AUTOSAR XML (schema 3.1.2)
package /Components/SWC_StopStrtEng
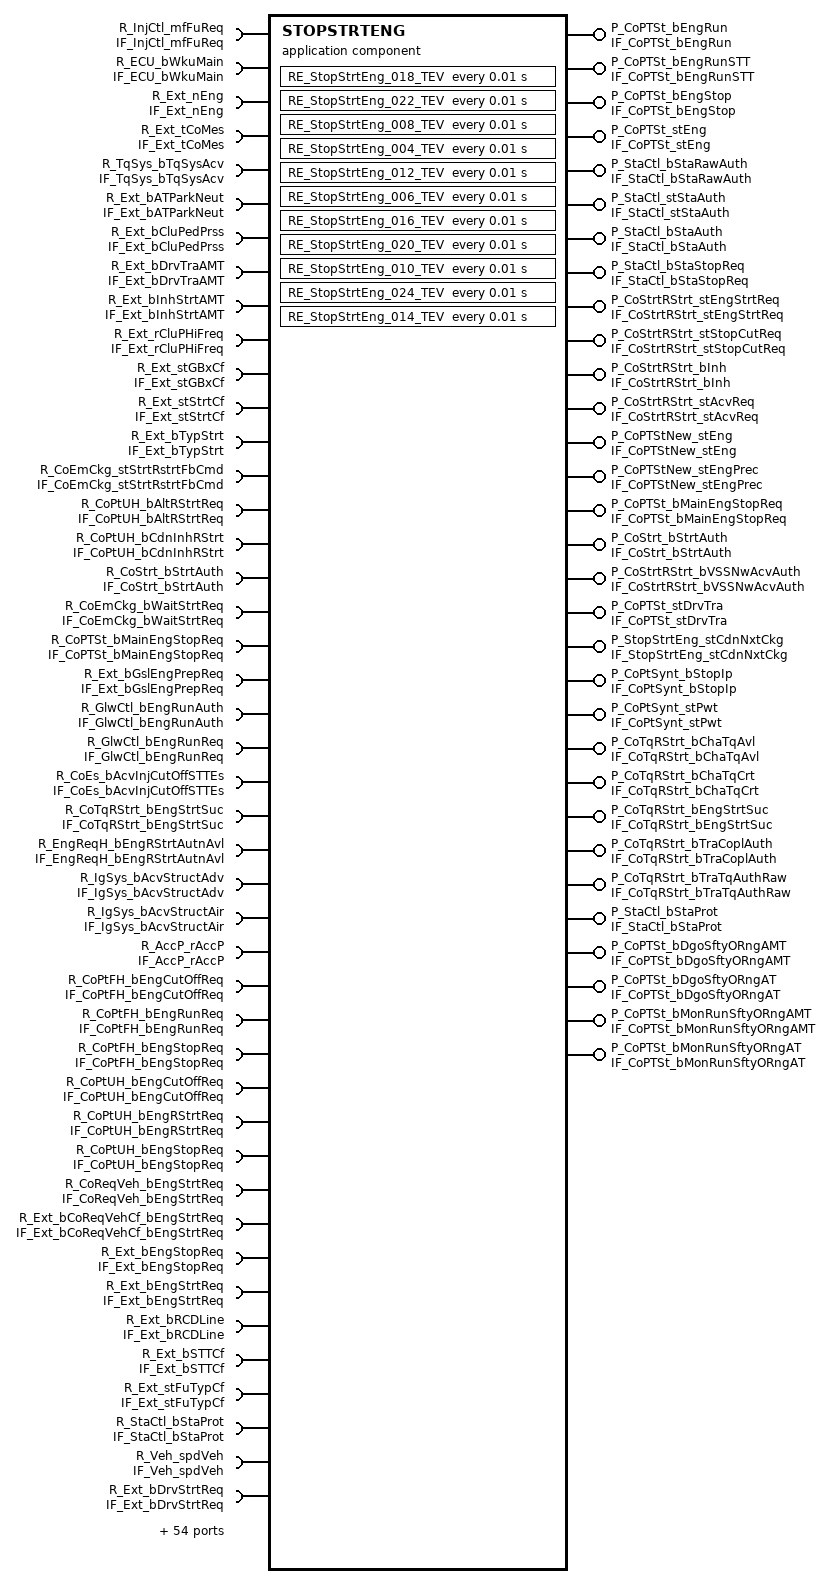
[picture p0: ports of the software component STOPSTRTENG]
  application software component type STOPSTRTENG
    91 x require port:
      R_InjCtl_mfFuReq: unqueued-receiver-com-spec{data-element=InjCtl_mfFuReq, init-value=InjCtl_mfFuReq_in, resync-time=0}, required-interface=IF_InjCtl_mfFuReq
      R_ECU_bWkuMain: unqueued-receiver-com-spec{data-element=ECU_bWkuMain, init-value=ConstantValue, resync-time=0}, required-interface=IF_ECU_bWkuMain
      R_Ext_nEng: unqueued-receiver-com-spec{data-element=Ext_nEng, init-value=ConstantValue1, resync-time=0}, required-interface=IF_Ext_nEng
      R_Ext_tCoMes: unqueued-receiver-com-spec{data-element=Ext_tCoMes, init-value=ConstantValue3, resync-time=0}, required-interface=IF_Ext_tCoMes
      R_TqSys_bTqSysAcv: unqueued-receiver-com-spec{data-element=TqSys_bTqSysAcv, init-value=TqSys_bTqSysAcv_in, resync-time=0}, required-interface=IF_TqSys_bTqSysAcv
      R_Ext_bATParkNeut: unqueued-receiver-com-spec{data-element=Ext_bATParkNeut, init-value=Ext_bATParkNeut_in, resync-time=0}, required-interface=IF_Ext_bATParkNeut
      R_Ext_bCluPedPrss: unqueued-receiver-com-spec{data-element=Ext_bCluPedPrss, init-value=ConstantValue5, resync-time=0}, required-interface=IF_Ext_bCluPedPrss
      R_Ext_bDrvTraAMT: unqueued-receiver-com-spec{data-element=Ext_bDrvTraAMT, init-value=Ext_bDrvTraAMT_in, resync-time=0}, required-interface=IF_Ext_bDrvTraAMT
      R_Ext_bInhStrtAMT: unqueued-receiver-com-spec{data-element=Ext_bInhStrtAMT, init-value=Ext_bInhStrtAMT_in, resync-time=0}, required-interface=IF_Ext_bInhStrtAMT
      R_Ext_rCluPHiFreq: unqueued-receiver-com-spec{data-element=Ext_rCluPHiFreq, init-value=ConstantValue7, resync-time=0}, required-interface=IF_Ext_rCluPHiFreq
      R_Ext_stGBxCf: unqueued-receiver-com-spec{data-element=Ext_stGBxCf, init-value=ConstantValue9, resync-time=0}, required-interface=IF_Ext_stGBxCf
      R_Ext_stStrtCf: unqueued-receiver-com-spec{data-element=Ext_stStrtCf, init-value=Ext_stStrtCf_in, resync-time=0}, required-interface=IF_Ext_stStrtCf
      R_Ext_bTypStrt: unqueued-receiver-com-spec{data-element=Ext_bTypStrt, init-value=Ext_bTypStrt_in, resync-time=0}, required-interface=IF_Ext_bTypStrt
      R_CoEmCkg_stStrtRstrtFbCmd: unqueued-receiver-com-spec{data-element=CoEmCkg_stStrtRstrtFbCmd, init-value=ConstantValue11, resync-time=0}, required-interface=IF_CoEmCkg_stStrtRstrtFbCmd
      R_CoPtUH_bAltRStrtReq: unqueued-receiver-com-spec{data-element=CoPtUH_bAltRStrtReq, init-value=ConstantValue13, resync-time=0}, required-interface=IF_CoPtUH_bAltRStrtReq
      R_CoPtUH_bCdnInhRStrt: unqueued-receiver-com-spec{data-element=CoPtUH_bCdnInhRStrt, init-value=ConstantValue15, resync-time=0}, required-interface=IF_CoPtUH_bCdnInhRStrt
      R_CoStrt_bStrtAuth: unqueued-receiver-com-spec{data-element=CoStrt_bStrtAuth, init-value=ConstantValue17, resync-time=0}, required-interface=IF_CoStrt_bStrtAuth
      R_CoEmCkg_bWaitStrtReq: unqueued-receiver-com-spec{data-element=CoEmCkg_bWaitStrtReq, init-value=ConstantValue19, resync-time=0}, required-interface=IF_CoEmCkg_bWaitStrtReq
      R_CoPTSt_bMainEngStopReq: unqueued-receiver-com-spec{data-element=CoPTSt_bMainEngStopReq, init-value=ConstantValue21, resync-time=0}, required-interface=IF_CoPTSt_bMainEngStopReq
      R_Ext_bGslEngPrepReq: unqueued-receiver-com-spec{data-element=Ext_bGslEngPrepReq, init-value=Ext_bGslEngPrepReq_in, resync-time=0}, required-interface=IF_Ext_bGslEngPrepReq
      R_GlwCtl_bEngRunAuth: unqueued-receiver-com-spec{data-element=GlwCtl_bEngRunAuth, init-value=GlwCtl_bEngRunAuth_in, resync-time=0}, required-interface=IF_GlwCtl_bEngRunAuth
      R_GlwCtl_bEngRunReq: unqueued-receiver-com-spec{data-element=GlwCtl_bEngRunReq, init-value=GlwCtl_bEngRunReq_in, resync-time=0}, required-interface=IF_GlwCtl_bEngRunReq
      R_CoEs_bAcvInjCutOffSTTEs: unqueued-receiver-com-spec{data-element=CoEs_bAcvInjCutOffSTTEs, init-value=CoEs_bAcvInjCutOffSTTEs_in, resync-time=0}, required-interface=IF_CoEs_bAcvInjCutOffSTTEs
      R_CoTqRStrt_bEngStrtSuc: unqueued-receiver-com-spec{data-element=CoTqRStrt_bEngStrtSuc, init-value=ConstantValue23, resync-time=0}, required-interface=IF_CoTqRStrt_bEngStrtSuc
      R_EngReqH_bEngRStrtAutnAvl: unqueued-receiver-com-spec{data-element=EngReqH_bEngRStrtAutnAvl, init-value=ConstantValue25, resync-time=0}, required-interface=IF_EngReqH_bEngRStrtAutnAvl
      R_IgSys_bAcvStructAdv: unqueued-receiver-com-spec{data-element=IgSys_bAcvStructAdv, init-value=ConstantValue27, resync-time=0}, required-interface=IF_IgSys_bAcvStructAdv
      R_IgSys_bAcvStructAir: unqueued-receiver-com-spec{data-element=IgSys_bAcvStructAir, init-value=ConstantValue29, resync-time=0}, required-interface=IF_IgSys_bAcvStructAir
      R_AccP_rAccP: unqueued-receiver-com-spec{data-element=AccP_rAccP, init-value=ConstantValue31, resync-time=0}, required-interface=IF_AccP_rAccP
      R_CoPtFH_bEngCutOffReq: unqueued-receiver-com-spec{data-element=CoPtFH_bEngCutOffReq, init-value=CoPtFH_bEngCutOffReq_in, resync-time=0}, required-interface=IF_CoPtFH_bEngCutOffReq
      R_CoPtFH_bEngRunReq: unqueued-receiver-com-spec{data-element=CoPtFH_bEngRunReq, init-value=CoPtFH_bEngRunReq_in, resync-time=0}, required-interface=IF_CoPtFH_bEngRunReq
      R_CoPtFH_bEngStopReq: unqueued-receiver-com-spec{data-element=CoPtFH_bEngStopReq, init-value=CoPtFH_bEngStopReq_in, resync-time=0}, required-interface=IF_CoPtFH_bEngStopReq
      R_CoPtUH_bEngCutOffReq: unqueued-receiver-com-spec{data-element=CoPtUH_bEngCutOffReq, init-value=ConstantValue33, resync-time=0}, required-interface=IF_CoPtUH_bEngCutOffReq
      R_CoPtUH_bEngRStrtReq: unqueued-receiver-com-spec{data-element=CoPtUH_bEngRStrtReq, init-value=ConstantValue35, resync-time=0}, required-interface=IF_CoPtUH_bEngRStrtReq
      R_CoPtUH_bEngStopReq: unqueued-receiver-com-spec{data-element=CoPtUH_bEngStopReq, init-value=ConstantValue37, resync-time=0}, required-interface=IF_CoPtUH_bEngStopReq
      R_CoReqVeh_bEngStrtReq: unqueued-receiver-com-spec{data-element=CoReqVeh_bEngStrtReq, init-value=CoReqVeh_bEngStrtReq_in, resync-time=0}, required-interface=IF_CoReqVeh_bEngStrtReq
      R_Ext_bCoReqVehCf_bEngStrtReq: unqueued-receiver-com-spec{data-element=Ext_bCoReqVehCf_bEngStrtReq, init-value=Ext_bCoReqVehCf_bEngStrtReq_in, resync-time=0}, required-interface=IF_Ext_bCoReqVehCf_bEngStrtReq
      R_Ext_bEngStopReq: unqueued-receiver-com-spec{data-element=Ext_bEngStopReq, init-value=Ext_bEngStopReq_in, resync-time=0}, required-interface=IF_Ext_bEngStopReq
      R_Ext_bEngStrtReq: unqueued-receiver-com-spec{data-element=Ext_bEngStrtReq, init-value=Ext_bEngStrtReq_in, resync-time=0}, required-interface=IF_Ext_bEngStrtReq
      R_Ext_bRCDLine: unqueued-receiver-com-spec{data-element=Ext_bRCDLine, init-value=ConstantValue39, resync-time=0}, required-interface=IF_Ext_bRCDLine
      R_Ext_bSTTCf: unqueued-receiver-com-spec{data-element=Ext_bSTTCf, init-value=ConstantValue41, resync-time=0}, required-interface=IF_Ext_bSTTCf
      R_Ext_stFuTypCf: unqueued-receiver-com-spec{data-element=Ext_stFuTypCf, init-value=ConstantValue43, resync-time=0}, required-interface=IF_Ext_stFuTypCf
      R_StaCtl_bStaProt: unqueued-receiver-com-spec{data-element=StaCtl_bStaProt, init-value=StaCtl_bStaProt_in, resync-time=0}, required-interface=IF_StaCtl_bStaProt
      R_Veh_spdVeh: unqueued-receiver-com-spec{data-element=Veh_spdVeh, init-value=ConstantValue45, resync-time=0}, required-interface=IF_Veh_spdVeh
      R_Ext_bDrvStrtReq: unqueued-receiver-com-spec{data-element=Ext_bDrvStrtReq, init-value=Ext_bDrvStrtReq_in, resync-time=0}, required-interface=IF_Ext_bDrvStrtReq
      R_StaCtl_bStaAuth: unqueued-receiver-com-spec{data-element=StaCtl_bStaAuth, init-value=StaCtl_bStaAuth_in, resync-time=0}, required-interface=IF_StaCtl_bStaAuth
      R_Ext_bBrkPedPrss: unqueued-receiver-com-spec{data-element=Ext_bBrkPedPrss, init-value=ConstantValue47, resync-time=0}, required-interface=IF_Ext_bBrkPedPrss
      R_Ext_posnGBxLev: unqueued-receiver-com-spec{data-element=Ext_posnGBxLev, init-value=ConstantValue49, resync-time=0}, required-interface=IF_Ext_posnGBxLev
      R_CoPtASE_bAltRStrtTypASEReq: unqueued-receiver-com-spec{data-element=CoPtASE_bAltRStrtTypASEReq, init-value=ConstantValue51, resync-time=0}, required-interface=IF_CoPtASE_bAltRStrtTypASEReq
      R_CoPtASE_bAltStrtTypASEReq: unqueued-receiver-com-spec{data-element=CoPtASE_bAltStrtTypASEReq, init-value=CoPtASE_bAltStrtTypASEReq_in, resync-time=0}, required-interface=IF_CoPtASE_bAltStrtTypASEReq
      R_CoPtASE_bCdnInhRStrt: unqueued-receiver-com-spec{data-element=CoPtASE_bCdnInhRStrt, init-value=ConstantValue53, resync-time=0}, required-interface=IF_CoPtASE_bCdnInhRStrt
      R_CoPtASE_bEngCutOffReq: unqueued-receiver-com-spec{data-element=CoPtASE_bEngCutOffReq, init-value=ConstantValue55, resync-time=0}, required-interface=IF_CoPtASE_bEngCutOffReq
      R_CoPtASE_bEngRStrtTypASEReq: unqueued-receiver-com-spec{data-element=CoPtASE_bEngRStrtTypASEReq, init-value=ConstantValue57, resync-time=0}, required-interface=IF_CoPtASE_bEngRStrtTypASEReq
      R_CoPtASE_bEngStallReq: unqueued-receiver-com-spec{data-element=CoPtASE_bEngStallReq, init-value=ConstantValue59, resync-time=0}, required-interface=IF_CoPtASE_bEngStallReq
      R_CoPtASE_bEngStrtTypASEReq: unqueued-receiver-com-spec{data-element=CoPtASE_bEngStrtTypASEReq, init-value=CoPtASE_bEngStrtTypASEReq_in, resync-time=0}, required-interface=IF_CoPtASE_bEngStrtTypASEReq
      R_CoPtASE_bVSSNwAcvAuth: unqueued-receiver-com-spec{data-element=CoPtASE_bVSSNwAcvAuth, init-value=ConstantValue61, resync-time=0}, required-interface=IF_CoPtASE_bVSSNwAcvAuth
      R_CoPTStNew_stEng: unqueued-receiver-com-spec{data-element=CoPTStNew_stEng, init-value=ConstantValue63, resync-time=0}, required-interface=IF_CoPTStNew_stEng
      R_CoPtUH_bVSSNwAcvAuth: unqueued-receiver-com-spec{data-element=CoPtUH_bVSSNwAcvAuth, init-value=ConstantValue65, resync-time=0}, required-interface=IF_CoPtUH_bVSSNwAcvAuth
      R_CoPtUH_bEngStallReq: unqueued-receiver-com-spec{data-element=CoPtUH_bEngStallReq, init-value=ConstantValue67, resync-time=0}, required-interface=IF_CoPtUH_bEngStallReq
      R_CoSync_bDetNNull: unqueued-receiver-com-spec{data-element=CoSync_bDetNNull, init-value=ConstantValue69, resync-time=0}, required-interface=IF_CoSync_bDetNNull
      R_Ext_bASECf: unqueued-receiver-com-spec{data-element=Ext_bASECf, init-value=Ext_bASECf_in, resync-time=0}, required-interface=IF_Ext_bASECf
      R_TqAdp_stCdnNxtCkg: unqueued-receiver-com-spec{data-element=TqAdp_stCdnNxtCkg, init-value=TqAdp_stCdnNxtCkg_in, resync-time=0}, required-interface=IF_TqAdp_stCdnNxtCkg
      R_CoOptmEl_stElEProv: unqueued-receiver-com-spec{data-element=CoOptmEl_stElEProv, init-value=ConstantValue71, resync-time=0}, required-interface=IF_CoOptmEl_stElEProv
      R_CoPtASE_stPwt: unqueued-receiver-com-spec{data-element=CoPtASE_stPwt, init-value=ConstantValue73, resync-time=0}, required-interface=IF_CoPtASE_stPwt
      R_CoPtUH_stPwt: unqueued-receiver-com-spec{data-element=CoPtUH_stPwt, init-value=ConstantValue75, resync-time=0}, required-interface=IF_CoPtUH_stPwt
      R_CoPTSt_stDrvTra: unqueued-receiver-com-spec{data-element=CoPTSt_stDrvTra, init-value=CoPTSt_stDrvTra_in, resync-time=0}, required-interface=IF_CoPTSt_stDrvTra
      R_TqSys_nTarIdl: unqueued-receiver-com-spec{data-element=TqSys_nTarIdl, init-value=ConstantValue77, resync-time=0}, required-interface=IF_TqSys_nTarIdl
      R_Ext_tOilMes: unqueued-receiver-com-spec{data-element=Ext_tOilMes, init-value=ConstantValue79, resync-time=0}, required-interface=IF_Ext_tOilMes
      R_PredEs_nFast: unqueued-receiver-com-spec{data-element=PredEs_nFast, init-value=ConstantValue81, resync-time=0}, required-interface=IF_PredEs_nFast
      R_CoPt_bSIP: unqueued-receiver-com-spec{data-element=CoPt_bSIP, init-value=ConstantValue83, resync-time=0}, required-interface=IF_CoPt_bSIP
      R_Ext_pAirExtMes: unqueued-receiver-com-spec{data-element=Ext_pAirExtMes, init-value=ConstantValue85, resync-time=0}, required-interface=IF_Ext_pAirExtMes
      R_Afts_bSpcFactOffDeacInh: unqueued-receiver-com-spec{data-element=Afts_bSpcFactOffDeacInh, init-value=Afts_bSpcFactOffDeacInh_in, resync-time=0}, required-interface=IF_Afts_bSpcFactOffDeacInh
      R_Afts_bSpcFactOnDeacInh: unqueued-receiver-com-spec{data-element=Afts_bSpcFactOnDeacInh, init-value=Afts_bSpcFactOnDeacInh_in, resync-time=0}, required-interface=IF_Afts_bSpcFactOnDeacInh
      R_CoTqRStrt_bTraTqAuthRaw: unqueued-receiver-com-spec{data-element=CoTqRStrt_bTraTqAuthRaw, init-value=ConstantValue87, resync-time=0}, required-interface=IF_CoTqRStrt_bTraTqAuthRaw
      R_PARM_bEngRstrtAutnAvl: unqueued-receiver-com-spec{data-element=PARM_bEngRstrtAutnAvl, init-value=ConstantValue89, resync-time=0}, required-interface=IF_PARM_bEngRstrtAutnAvl
      R_CoEmSTT_tiVSSTmrStrtAuth: unqueued-receiver-com-spec{data-element=CoEmSTT_tiVSSTmrStrtAuth, init-value=ConstantValue91, resync-time=0}, required-interface=IF_CoEmSTT_tiVSSTmrStrtAuth
      R_EngReqH_bDetPresAirUnfav: unqueued-receiver-com-spec{data-element=EngReqH_bDetPresAirUnfav, init-value=EngReqH_bDetPresAirUnfav_in, resync-time=0}, required-interface=IF_EngReqH_bDetPresAirUnfav
      R_CoPTSt_bEngRunSTT: unqueued-receiver-com-spec{data-element=CoPTSt_bEngRunSTT, init-value=CoPTSt_bEngRunSTT_in, resync-time=0}, required-interface=IF_CoPTSt_bEngRunSTT
      R_Ext_bDgoSenPN: unqueued-receiver-com-spec{data-element=Ext_bDgoSenPN, init-value=Ext_bDgoSenPN_in, resync-time=0}, required-interface=IF_Ext_bDgoSenPN
      R_Ext_bAcvInjCutOff: unqueued-receiver-com-spec{data-element=Ext_bAcvInjCutOff, init-value=Ext_bAcvInjCutOff_in, resync-time=0}, required-interface=IF_Ext_bAcvInjCutOff
      R_Sfty_bInhDrvTraSfty: unqueued-receiver-com-spec{data-element=Sfty_bInhDrvTraSfty, init-value=Sfty_bInhDrvTraSfty_in, resync-time=0}, required-interface=IF_Sfty_bInhDrvTraSfty
      R_FRM_bAcvDrvTraInvld: required-interface=FunctionInhibition
      R_FRM_bInhSta: required-interface=FunctionInhibition
      R_FRM_bAcvCoPTStByp_nEng: required-interface=FunctionInhibition
      R_FRM_bAcvCoPTStByp_spdVeh: required-interface=FunctionInhibition
      R_FRM_bAcvCoPTStEngStop: required-interface=FunctionInhibition
      R_FRM_bAcvEngCutOffRCDLo: required-interface=FunctionInhibition
      R_FRM_bInhEngCutOff: required-interface=FunctionInhibition
      R_FRM_bInhSTT: required-interface=FunctionInhibition
      R_FRM_bAcvEngCutOff: required-interface=FunctionInhibition
      R_FRM_bStrtPrf: required-interface=FunctionInhibition
      R_FRM_bAcvPrmCoTqRStrt: required-interface=FunctionInhibition
    27 x provide port:
      P_CoPTSt_bEngRun: unqueued-sender-com-spec{data-element=CoPTSt_bEngRun, can-invalidate=false, init-value=CoPTSt_bEngRun_out}, provided-interface=IF_CoPTSt_bEngRun
      P_CoPTSt_bEngRunSTT: unqueued-sender-com-spec{data-element=CoPTSt_bEngRunSTT, can-invalidate=false, init-value=CoPTSt_bEngRunSTT_out}, provided-interface=IF_CoPTSt_bEngRunSTT
      P_CoPTSt_bEngStop: unqueued-sender-com-spec{data-element=CoPTSt_bEngStop, can-invalidate=false, init-value=CoPTSt_bEngStop_out}, provided-interface=IF_CoPTSt_bEngStop
      P_CoPTSt_stEng: unqueued-sender-com-spec{data-element=CoPTSt_stEng, can-invalidate=false, init-value=ConstantValue93}, provided-interface=IF_CoPTSt_stEng
      P_StaCtl_bStaRawAuth: unqueued-sender-com-spec{data-element=StaCtl_bStaRawAuth, can-invalidate=false, init-value=StaCtl_bStaRawAuth_out}, provided-interface=IF_StaCtl_bStaRawAuth
      P_StaCtl_stStaAuth: unqueued-sender-com-spec{data-element=StaCtl_stStaAuth, can-invalidate=false, init-value=StaCtl_stStaAuth_out}, provided-interface=IF_StaCtl_stStaAuth
      P_StaCtl_bStaAuth: unqueued-sender-com-spec{data-element=StaCtl_bStaAuth, can-invalidate=false, init-value=StaCtl_bStaAuth_out}, provided-interface=IF_StaCtl_bStaAuth
      P_StaCtl_bStaStopReq: unqueued-sender-com-spec{data-element=StaCtl_bStaStopReq, can-invalidate=false, init-value=StaCtl_bStaStopReq_out}, provided-interface=IF_StaCtl_bStaStopReq
      P_CoStrtRStrt_stEngStrtReq: unqueued-sender-com-spec{data-element=CoStrtRStrt_stEngStrtReq, can-invalidate=false, init-value=ConstantValue95}, provided-interface=IF_CoStrtRStrt_stEngStrtReq
      P_CoStrtRStrt_stStopCutReq: unqueued-sender-com-spec{data-element=CoStrtRStrt_stStopCutReq, can-invalidate=false, init-value=CoStrtRStrt_stStopCutReq_out}, provided-interface=IF_CoStrtRStrt_stStopCutReq
      P_CoStrtRStrt_bInh: unqueued-sender-com-spec{data-element=CoStrtRStrt_bInh, can-invalidate=false, init-value=ConstantValue97}, provided-interface=IF_CoStrtRStrt_bInh
      P_CoStrtRStrt_stAcvReq: unqueued-sender-com-spec{data-element=CoStrtRStrt_stAcvReq, can-invalidate=false, init-value=ConstantValue99}, provided-interface=IF_CoStrtRStrt_stAcvReq
      P_CoPTStNew_stEng: unqueued-sender-com-spec{data-element=CoPTStNew_stEng, can-invalidate=false, init-value=ConstantValue101}, provided-interface=IF_CoPTStNew_stEng
      P_CoPTStNew_stEngPrec: unqueued-sender-com-spec{data-element=CoPTStNew_stEngPrec, can-invalidate=false, init-value=CoPTStNew_stEngPrec_out}, provided-interface=IF_CoPTStNew_stEngPrec
      P_CoPTSt_bMainEngStopReq: unqueued-sender-com-spec{data-element=CoPTSt_bMainEngStopReq, can-invalidate=false, init-value=ConstantValue103}, provided-interface=IF_CoPTSt_bMainEngStopReq
      P_CoStrt_bStrtAuth: unqueued-sender-com-spec{data-element=CoStrt_bStrtAuth, can-invalidate=false, init-value=ConstantValue105}, provided-interface=IF_CoStrt_bStrtAuth
      P_CoStrtRStrt_bVSSNwAcvAuth: unqueued-sender-com-spec{data-element=CoStrtRStrt_bVSSNwAcvAuth, can-invalidate=false, init-value=CoStrtRStrt_bVSSNwAcvAuth_out}, provided-interface=IF_CoStrtRStrt_bVSSNwAcvAuth
      P_CoPTSt_stDrvTra: unqueued-sender-com-spec{data-element=CoPTSt_stDrvTra, can-invalidate=false, init-value=CoPTSt_stDrvTra_out}, provided-interface=IF_CoPTSt_stDrvTra
      P_StopStrtEng_stCdnNxtCkg: unqueued-sender-com-spec{data-element=StopStrtEng_stCdnNxtCkg, can-invalidate=false, init-value=ConstantValue107}, provided-interface=IF_StopStrtEng_stCdnNxtCkg
      P_CoPtSynt_bStopIp: unqueued-sender-com-spec{data-element=CoPtSynt_bStopIp, can-invalidate=false, init-value=CoPtSynt_bStopIp_out}, provided-interface=IF_CoPtSynt_bStopIp
      P_CoPtSynt_stPwt: unqueued-sender-com-spec{data-element=CoPtSynt_stPwt, can-invalidate=false, init-value=ConstantValue109}, provided-interface=IF_CoPtSynt_stPwt
      P_CoTqRStrt_bChaTqAvl: unqueued-sender-com-spec{data-element=CoTqRStrt_bChaTqAvl, can-invalidate=false, init-value=CoTqRStrt_bChaTqAvl_out}, provided-interface=IF_CoTqRStrt_bChaTqAvl
      P_CoTqRStrt_bChaTqCrt: unqueued-sender-com-spec{data-element=CoTqRStrt_bChaTqCrt, can-invalidate=false, init-value=CoTqRStrt_bChaTqCrt_out}, provided-interface=IF_CoTqRStrt_bChaTqCrt
      P_CoTqRStrt_bEngStrtSuc: unqueued-sender-com-spec{data-element=CoTqRStrt_bEngStrtSuc, can-invalidate=false, init-value=ConstantValue111}, provided-interface=IF_CoTqRStrt_bEngStrtSuc
      P_CoTqRStrt_bTraCoplAuth: unqueued-sender-com-spec{data-element=CoTqRStrt_bTraCoplAuth, can-invalidate=false, init-value=CoTqRStrt_bTraCoplAuth_out}, provided-interface=IF_CoTqRStrt_bTraCoplAuth
      P_CoTqRStrt_bTraTqAuthRaw: unqueued-sender-com-spec{data-element=CoTqRStrt_bTraTqAuthRaw, can-invalidate=false, init-value=ConstantValue113}, provided-interface=IF_CoTqRStrt_bTraTqAuthRaw
      P_StaCtl_bStaProt: unqueued-sender-com-spec{data-element=StaCtl_bStaProt, can-invalidate=false, init-value=StaCtl_bStaProt_out}, provided-interface=IF_StaCtl_bStaProt
    7 x require port:
      R_CoSTT_ORngCutOffReq: required-interface=DiagnosticMonitor
      R_CoSTT_ORngStopReq: required-interface=DiagnosticMonitor
      R_CoPTSt_ORngMplReq: required-interface=DiagnosticMonitor
      R_CoPTSt_SftyORngAMT: required-interface=DiagnosticMonitor
      R_CoPTSt_SftyORngAT: required-interface=DiagnosticMonitor
      R_UCE_stWkuMainRelSt: required-interface=IF_UCE_stWkuMainRelSt
      R_EcuM_CurrentMode: required-interface=EcuM_CurrentMode
    4 x provide port:
      P_CoPTSt_bDgoSftyORngAMT: unqueued-sender-com-spec{data-element=CoPTSt_bDgoSftyORngAMT, can-invalidate=false, init-value=CoPTSt_bDgoSftyORngAMT_Cst}, provided-interface=IF_CoPTSt_bDgoSftyORngAMT
      P_CoPTSt_bDgoSftyORngAT: unqueued-sender-com-spec{data-element=CoPTSt_bDgoSftyORngAT, can-invalidate=false, init-value=CoPTSt_bDgoSftyORngAT_Cst}, provided-interface=IF_CoPTSt_bDgoSftyORngAT
      P_CoPTSt_bMonRunSftyORngAMT: unqueued-sender-com-spec{data-element=CoPTSt_bMonRunSftyORngAMT, can-invalidate=false, init-value=CoPTSt_bMonRunSftyORngAMT_Cst}, provided-interface=IF_CoPTSt_bMonRunSftyORngAMT
      P_CoPTSt_bMonRunSftyORngAT: unqueued-sender-com-spec{data-element=CoPTSt_bMonRunSftyORngAT, can-invalidate=false, init-value=CoPTSt_bMonRunSftyORngAT_Cst}, provided-interface=IF_CoPTSt_bMonRunSftyORngAT
  125 x constant specification:
    Afts_bSpcFactOffDeacInh_in
      value:
        boolean literal Afts_bSpcFactOffDeacInh_in: type=DT_Afts_bSpcFactOffDeacInh, value=true
    Afts_bSpcFactOnDeacInh_in
      value:
        boolean literal Afts_bSpcFactOnDeacInh_in: type=DT_Afts_bSpcFactOnDeacInh, value=false
    CoEs_bAcvInjCutOffSTTEs_in
      value:
        boolean literal CoEs_bAcvInjCutOffSTTEs_in: type=DT_CoEs_bAcvInjCutOffSTTEs, value=false
    ConstantValue
      value:
        boolean literal ConstantValue: type=DT_ECU_bWkuMain, value=false
    ConstantValue1
      value:
        integer literal ConstantValue1: type=DT_Ext_nEng, value=0
    ConstantValue101
      value:
        integer literal ConstantValue101: type=DT_CoPTStNew_stEng, value=1
    ConstantValue103
      value:
        boolean literal ConstantValue103: type=DT_CoPTSt_bMainEngStopReq, value=false
    ConstantValue105
      value:
        boolean literal ConstantValue105: type=DT_CoStrt_bStrtAuth, value=false
    ConstantValue107
      value:
        integer literal ConstantValue107: type=DT_StopStrtEng_stCdnNxtCkg, value=0
    ConstantValue109
      value:
        integer literal ConstantValue109: type=DT_CoPtSynt_stPwt, value=1
    ConstantValue11
      value:
        integer literal ConstantValue11: type=DT_CoEmCkg_stStrtRstrtFbCmd, value=0
    ConstantValue111
      value:
        boolean literal ConstantValue111: type=DT_CoTqRStrt_bEngStrtSuc, value=false
    ConstantValue113
      value:
        boolean literal ConstantValue113: type=DT_CoTqRStrt_bTraTqAuthRaw, value=false
    ConstantValue13
      value:
        boolean literal ConstantValue13: type=DT_CoPtUH_bAltRStrtReq, value=false
    ConstantValue15
      value:
        boolean literal ConstantValue15: type=DT_CoPtUH_bCdnInhRStrt, value=false
    ConstantValue17
      value:
        boolean literal ConstantValue17: type=DT_CoStrt_bStrtAuth, value=false
    ConstantValue19
      value:
        boolean literal ConstantValue19: type=DT_CoEmCkg_bWaitStrtReq, value=false
    ConstantValue21
      value:
        boolean literal ConstantValue21: type=DT_CoPTSt_bMainEngStopReq, value=false
    ConstantValue23
      value:
        boolean literal ConstantValue23: type=DT_CoTqRStrt_bEngStrtSuc, value=false
    ConstantValue25
      value:
        boolean literal ConstantValue25: type=DT_EngReqH_bEngRStrtAutnAvl, value=false
    ConstantValue27
      value:
        boolean literal ConstantValue27: type=DT_IgSys_bAcvStructAdv, value=false
    ConstantValue29
      value:
        boolean literal ConstantValue29: type=DT_IgSys_bAcvStructAir, value=false
    ConstantValue3
      value:
        integer literal ConstantValue3: type=DT_Ext_tCoMes, value=20
    ConstantValue31
      value:
        integer literal ConstantValue31: type=DT_AccP_rAccP, value=0
    ConstantValue33
      value:
        boolean literal ConstantValue33: type=DT_CoPtUH_bEngCutOffReq, value=false
    ConstantValue35
      value:
        boolean literal ConstantValue35: type=DT_CoPtUH_bEngRStrtReq, value=false
    ConstantValue37
      value:
        boolean literal ConstantValue37: type=DT_CoPtUH_bEngStopReq, value=false
    ConstantValue39
      value:
        boolean literal ConstantValue39: type=DT_Ext_bRCDLine, value=false
    ConstantValue41
      value:
        boolean literal ConstantValue41: type=DT_Ext_bSTTCf, value=false
    ConstantValue43
      value:
        integer literal ConstantValue43: type=DT_Ext_stFuTypCf, value=0
    ConstantValue45
      value:
        integer literal ConstantValue45: type=DT_Veh_spdVeh, value=0
    ConstantValue47
      value:
        boolean literal ConstantValue47: type=DT_Ext_bBrkPedPrss, value=false
    ConstantValue49
      value:
        integer literal ConstantValue49: type=DT_Ext_posnGBxLev, value=0
    ConstantValue5
      value:
        boolean literal ConstantValue5: type=DT_Ext_bCluPedPrss, value=false
    ConstantValue51
      value:
        boolean literal ConstantValue51: type=DT_CoPtASE_bAltRStrtTypASEReq, value=false
    ConstantValue53
      value:
        boolean literal ConstantValue53: type=DT_CoPtASE_bCdnInhRStrt, value=true
    ConstantValue55
      value:
        boolean literal ConstantValue55: type=DT_CoPtASE_bEngCutOffReq, value=false
    ConstantValue57
      value:
        boolean literal ConstantValue57: type=DT_CoPtASE_bEngRStrtTypASEReq, value=false
    ConstantValue59
      value:
        boolean literal ConstantValue59: type=DT_CoPtASE_bEngStallReq, value=false
    ConstantValue61
      value:
        boolean literal ConstantValue61: type=DT_CoPtASE_bVSSNwAcvAuth, value=false
    ConstantValue63
      value:
        integer literal ConstantValue63: type=DT_CoPTStNew_stEng, value=1
    ConstantValue65
      value:
        boolean literal ConstantValue65: type=DT_CoPtUH_bVSSNwAcvAuth, value=false
    ConstantValue67
      value:
        boolean literal ConstantValue67: type=DT_CoPtUH_bEngStallReq, value=false
    ConstantValue69
      value:
        boolean literal ConstantValue69: type=DT_CoSync_bDetNNull, value=false
    ConstantValue7
      value:
        integer literal ConstantValue7: type=DT_Ext_rCluPHiFreq, value=0
    ConstantValue71
      value:
        integer literal ConstantValue71: type=DT_CoOptmEl_stElEProv, value=1
    ConstantValue73
      value:
        integer literal ConstantValue73: type=DT_CoPtASE_stPwt, value=1
    ConstantValue75
      value:
        integer literal ConstantValue75: type=DT_CoPtUH_stPwt, value=1
    ConstantValue77
      value:
        integer literal ConstantValue77: type=DT_TqSys_nTarIdl, value=0
    ConstantValue79
      value:
        integer literal ConstantValue79: type=DT_Ext_tOilMes, value=0
    ConstantValue81
      value:
        integer literal ConstantValue81: type=DT_PredEs_nFast, value=0
    ConstantValue83
      value:
        boolean literal ConstantValue83: type=DT_CoPt_bSIP, value=false
    ConstantValue85
      value:
        integer literal ConstantValue85: type=DT_Ext_pAirExtMes, value=500
    ConstantValue87
      value:
        boolean literal ConstantValue87: type=DT_CoTqRStrt_bTraTqAuthRaw, value=false
    ConstantValue89
      value:
        boolean literal ConstantValue89: type=DT_PARM_bEngRstrtAutnAvl, value=false
    ConstantValue9
      value:
        integer literal ConstantValue9: type=DT_Ext_stGBxCf, value=0
    ConstantValue91
      value:
        integer literal ConstantValue91: type=DT_CoEmSTT_tiVSSTmrStrtAuth, value=0
    ConstantValue93
      value:
        integer literal ConstantValue93: type=DT_CoPTSt_stEng, value=1
    ConstantValue95
      value:
        integer literal ConstantValue95: type=DT_CoStrtRStrt_stEngStrtReq, value=0
    ConstantValue97
      value:
        boolean literal ConstantValue97: type=DT_CoStrtRStrt_bInh, value=true
    ConstantValue99
      value:
        integer literal ConstantValue99: type=DT_CoStrtRStrt_stAcvReq, value=0
    CoPtASE_bAltStrtTypASEReq_in
      value:
        boolean literal CoPtASE_bAltStrtTypASEReq_in: type=DT_CoPtASE_bAltStrtTypASEReq, value=false
    CoPtASE_bEngStrtTypASEReq_in
      value:
        boolean literal CoPtASE_bEngStrtTypASEReq_in: type=DT_CoPtASE_bEngStrtTypASEReq, value=false
    CoPtFH_bEngCutOffReq_in
      value:
        boolean literal CoPtFH_bEngCutOffReq_in: type=DT_CoPtFH_bEngCutOffReq, value=false
    CoPtFH_bEngRunReq_in
      value:
        boolean literal CoPtFH_bEngRunReq_in: type=DT_CoPtFH_bEngRunReq, value=false
    CoPtFH_bEngStopReq_in
      value:
        boolean literal CoPtFH_bEngStopReq_in: type=DT_CoPtFH_bEngStopReq, value=true
    CoPTSt_bDgoSftyORngAMT_Cst
      value:
        boolean literal CoPTSt_bDgoSftyORngAMT_Cst: type=DT_CoPTSt_bDgoSftyORngAMT, value=false
    CoPTSt_bDgoSftyORngAT_Cst
      value:
        boolean literal CoPTSt_bDgoSftyORngAT_Cst: type=DT_CoPTSt_bDgoSftyORngAT, value=false
    CoPTSt_bEngRun_out
      value:
        boolean literal CoPTSt_bEngRun_out: type=DT_CoPTSt_bEngRun, value=false
    CoPTSt_bEngRunSTT_in
      value:
        boolean literal CoPTSt_bEngRunSTT_in: type=DT_CoPTSt_bEngRunSTT, value=false
    CoPTSt_bEngRunSTT_out
      value:
        boolean literal CoPTSt_bEngRunSTT_out: type=DT_CoPTSt_bEngRunSTT, value=false
    CoPTSt_bEngStop_out
      value:
        boolean literal CoPTSt_bEngStop_out: type=DT_CoPTSt_bEngStop, value=true
    CoPTSt_bEngStopReq_Cst
      value:
        boolean literal CoPTSt_bEngStopReq_Cst: type=DT_CoPTSt_bEngStopReq, value=false
    CoPTSt_bEngStrtGlblReq_Cst
      value:
        boolean literal CoPTSt_bEngStrtGlblReq_Cst: type=DT_CoPTSt_bEngStrtGlblReq, value=true
    CoPTSt_bEngStrtReqVld_Cst
      value:
        boolean literal CoPTSt_bEngStrtReqVld_Cst: type=DT_CoPTSt_bEngStrtReqVld, value=false
    CoPTSt_bMonRunSftyORngAMT_Cst
      value:
        boolean literal CoPTSt_bMonRunSftyORngAMT_Cst: type=DT_CoPTSt_bMonRunSftyORngAMT, value=false
    CoPTSt_bMonRunSftyORngAT_Cst
      value:
        boolean literal CoPTSt_bMonRunSftyORngAT_Cst: type=DT_CoPTSt_bMonRunSftyORngAT, value=false
    CoPTSt_stDrvTra_in
      value:
        integer literal CoPTSt_stDrvTra_in: type=DT_CoPTSt_stDrvTra, value=1
    CoPTSt_stDrvTra_out
      value:
        integer literal CoPTSt_stDrvTra_out: type=DT_CoPTSt_stDrvTra, value=1
    CoPTStNew_stEngPrec_out
      value:
        integer literal CoPTStNew_stEngPrec_out: type=DT_CoPTStNew_stEngPrec, value=12
    CoPtSynt_bStopIp_out
      value:
        boolean literal CoPtSynt_bStopIp_out: type=DT_CoPtSynt_bStopIp, value=false
    CoReqVeh_bEngStrtReq_in
      value:
        boolean literal CoReqVeh_bEngStrtReq_in: type=DT_CoReqVeh_bEngStrtReq, value=false
    CoStrt_bStrtReq_Cst
      value:
        boolean literal CoStrt_bStrtReq_Cst: type=DT_CoStrt_bStrtReq, value=false
    CoStrtRStrt_bVSSNwAcvAuth_out
      value:
        boolean literal CoStrtRStrt_bVSSNwAcvAuth_out: type=DT_CoStrtRStrt_bVSSNwAcvAuth, value=false
    CoStrtRStrt_stStopCutReq_out
      value:
        integer literal CoStrtRStrt_stStopCutReq_out: type=DT_CoStrtRStrt_stStopCutReq, value=0
    CoSTT_bEngCutOffReq_Cst
      value:
        boolean literal CoSTT_bEngCutOffReq_Cst: type=DT_CoSTT_bEngCutOffReq, value=false
    CoSTT_bEngRStrtReq_Cst
      value:
        boolean literal CoSTT_bEngRStrtReq_Cst: type=DT_CoSTT_bEngRStrtReq, value=false
    CoSTT_bEngStopReq_Cst
      value:
        boolean literal CoSTT_bEngStopReq_Cst: type=DT_CoSTT_bEngStopReq, value=false
    CoTqRStrt_bChaTqAvl_out
      value:
        boolean literal CoTqRStrt_bChaTqAvl_out: type=DT_CoTqRStrt_bChaTqAvl, value=false
    CoTqRStrt_bChaTqCrt_out
      value:
        boolean literal CoTqRStrt_bChaTqCrt_out: type=DT_CoTqRStrt_bChaTqCrt, value=false
    CoTqRStrt_bTraCoplAuth_out
      value:
        boolean literal CoTqRStrt_bTraCoplAuth_out: type=DT_CoTqRStrt_bTraCoplAuth, value=false
    EngReqH_bDetPresAirUnfav_in
      value:
        boolean literal EngReqH_bDetPresAirUnfav_in: type=DT_EngReqH_bDetPresAirUnfav, value=false
    Ext_bAcvInjCutOff_in
      value:
        boolean literal Ext_bAcvInjCutOff_in: type=DT_Ext_bAcvInjCutOff, value=false
    Ext_bASECf_in
      value:
        boolean literal Ext_bASECf_in: type=DT_Ext_bASECf, value=false
    Ext_bATParkNeut_in
      value:
        boolean literal Ext_bATParkNeut_in: type=DT_Ext_bATParkNeut, value=false
    Ext_bCoReqVehCf_bEngStrtReq_in
      value:
        boolean literal Ext_bCoReqVehCf_bEngStrtReq_in: type=DT_Ext_bCoReqVehCf_bEngStrtReq, value=false
    Ext_bDgoSenPN_in
      value:
        boolean literal Ext_bDgoSenPN_in: type=DT_Ext_bDgoSenPN, value=true
    Ext_bDrvStrtReq_in
      value:
        boolean literal Ext_bDrvStrtReq_in: type=DT_Ext_bDrvStrtReq, value=false
    Ext_bDrvTraAMT_in
      value:
        boolean literal Ext_bDrvTraAMT_in: type=DT_Ext_bDrvTraAMT, value=false
    Ext_bEngStopReq_in
      value:
        boolean literal Ext_bEngStopReq_in: type=DT_Ext_bEngStopReq, value=false
    Ext_bEngStrtReq_in
      value:
        boolean literal Ext_bEngStrtReq_in: type=DT_Ext_bEngStrtReq, value=false
    Ext_bGslEngPrepReq_in
      value:
        boolean literal Ext_bGslEngPrepReq_in: type=DT_Ext_bGslEngPrepReq, value=false
    Ext_bInhStrtAMT_in
      value:
        boolean literal Ext_bInhStrtAMT_in: type=DT_Ext_bInhStrtAMT, value=true
    Ext_bTypStrt_in
      value:
        boolean literal Ext_bTypStrt_in: type=DT_Ext_bTypStrt, value=false
    Ext_stStrtCf_in
      value:
        integer literal Ext_stStrtCf_in: type=DT_Ext_stStrtCf, value=0
    GlwCtl_bEngRunAuth_in
      value:
        boolean literal GlwCtl_bEngRunAuth_in: type=DT_GlwCtl_bEngRunAuth, value=true
    GlwCtl_bEngRunReq_in
      value:
        boolean literal GlwCtl_bEngRunReq_in: type=DT_GlwCtl_bEngRunReq, value=false
    InjCtl_mfFuReq_in
      value:
        integer literal InjCtl_mfFuReq_in: type=DT_InjCtl_mfFuReq, value=0
    Sfty_bInhDrvTraSfty_in
      value:
        boolean literal Sfty_bInhDrvTraSfty_in: type=DT_Sfty_bInhDrvTraSfty, value=false
    StaCtl_bEngPrepAcv_Cst
      value:
        boolean literal StaCtl_bEngPrepAcv_Cst: type=DT_StaCtl_bEngPrepAcv, value=false
    StaCtl_bEngPrepEngAuth_Cst
      value:
        boolean literal StaCtl_bEngPrepEngAuth_Cst: type=DT_StaCtl_bEngPrepEngAuth, value=false
    StaCtl_bEngRunPrepReq_Cst
      value:
        boolean literal StaCtl_bEngRunPrepReq_Cst: type=DT_StaCtl_bEngRunPrepReq, value=false
    StaCtl_bEngStrtAuth_Cst
      value:
        boolean literal StaCtl_bEngStrtAuth_Cst: type=DT_StaCtl_bEngStrtAuth, value=true
    StaCtl_bPrepStrtAuth_Cst
      value:
        boolean literal StaCtl_bPrepStrtAuth_Cst: type=DT_StaCtl_bPrepStrtAuth, value=false
    StaCtl_bPTProt_Cst
      value:
        boolean literal StaCtl_bPTProt_Cst: type=DT_StaCtl_bPTProt, value=false
    StaCtl_bStaAuth_in
      value:
        boolean literal StaCtl_bStaAuth_in: type=DT_StaCtl_bStaAuth, value=false
    StaCtl_bStaAuth_out
      value:
        boolean literal StaCtl_bStaAuth_out: type=DT_StaCtl_bStaAuth, value=false
    StaCtl_bStaProt_in
      value:
        boolean literal StaCtl_bStaProt_in: type=DT_StaCtl_bStaProt, value=false
    StaCtl_bStaProt_out
      value:
        boolean literal StaCtl_bStaProt_out: type=DT_StaCtl_bStaProt, value=false
    StaCtl_bStaRawAuth_out
      value:
        boolean literal StaCtl_bStaRawAuth_out: type=DT_StaCtl_bStaRawAuth, value=false
    StaCtl_bStaStopReq_out
      value:
        boolean literal StaCtl_bStaStopReq_out: type=DT_StaCtl_bStaStopReq, value=false
    StaCtl_stStaAuth_out
      value:
        integer literal StaCtl_stStaAuth_out: type=DT_StaCtl_stStaAuth, value=2
    StopStrtEng_bVSSNwAcvAuth_Cst
      value:
        boolean literal StopStrtEng_bVSSNwAcvAuth_Cst: type=DT_StopStrtEng_bVSSNwAcvAuth, value=false
    TqAdp_stCdnNxtCkg_in
      value:
        integer literal TqAdp_stCdnNxtCkg_in: type=DT_TqAdp_stCdnNxtCkg, value=0
    TqSys_bTqSysAcv_in
      value:
        boolean literal TqSys_bTqSysAcv_in: type=DT_TqSys_bTqSysAcv, value=false
  internal behavior IB_StopStrtEng: component=STOPSTRTENG
    timing event EV_StopStrtEng_018_TEV: mode-dependency=dependent-on-mode=R_UCE_stWkuMainRelSt.RCD_stWkuMainRelSt.Invalid, start-on-event=RE_StopStrtEng_018_TEV, period=0.01
    mode switch event EV_StopStrtEng_017_MSE: start-on-event=RE_StopStrtEng_017_MSE, activation=ENTRY, mode=R_EcuM_CurrentMode.currentMode.RUN
    timing event EV_StopStrtEng_022_TEV: mode-dependency=dependent-on-mode=R_UCE_stWkuMainRelSt.RCD_stWkuMainRelSt.Invalid, start-on-event=RE_StopStrtEng_022_TEV, period=0.01
    timing event EV_StopStrtEng_008_TEV: mode-dependency=dependent-on-mode=[R_UCE_stWkuMainRelSt.RCD_stWkuMainRelSt.PostMainWakeUp, R_UCE_stWkuMainRelSt.RCD_stWkuMainRelSt.Invalid], start-on-event=RE_StopStrtEng_008_TEV, period=0.01
    mode switch event EV_StopStrtEng_023_MSE: start-on-event=RE_StopStrtEng_023_MSE, activation=ENTRY, mode=R_EcuM_CurrentMode.currentMode.RUN
    timing event EV_StopStrtEng_004_TEV: mode-dependency=dependent-on-mode=R_UCE_stWkuMainRelSt.RCD_stWkuMainRelSt.Invalid, start-on-event=RE_StopStrtEng_004_TEV, period=0.01
    mode switch event EV_StopStrtEng_003_MSE: start-on-event=RE_StopStrtEng_003_MSE, activation=ENTRY, mode=R_EcuM_CurrentMode.currentMode.RUN
    mode switch event EV_StopStrtEng_005_MSE: start-on-event=RE_StopStrtEng_005_MSE, activation=ENTRY, mode=R_EcuM_CurrentMode.currentMode.RUN
    timing event EV_StopStrtEng_012_TEV: mode-dependency=dependent-on-mode=R_UCE_stWkuMainRelSt.RCD_stWkuMainRelSt.Invalid, start-on-event=RE_StopStrtEng_012_TEV, period=0.01
    mode switch event EV_StopStrtEng_019_MSE: start-on-event=RE_StopStrtEng_019_MSE, activation=ENTRY, mode=R_EcuM_CurrentMode.currentMode.RUN
    mode switch event EV_StopStrtEng_011_MSE: start-on-event=RE_StopStrtEng_011_MSE, activation=ENTRY, mode=R_EcuM_CurrentMode.currentMode.RUN
    timing event EV_StopStrtEng_006_TEV: mode-dependency=dependent-on-mode=R_UCE_stWkuMainRelSt.RCD_stWkuMainRelSt.Invalid, start-on-event=RE_StopStrtEng_006_TEV, period=0.01
    timing event EV_StopStrtEng_016_TEV: mode-dependency=dependent-on-mode=R_UCE_stWkuMainRelSt.RCD_stWkuMainRelSt.Invalid, start-on-event=RE_StopStrtEng_016_TEV, period=0.01
    mode switch event EV_StopStrtEng_021_MSE: start-on-event=RE_StopStrtEng_021_MSE, activation=ENTRY, mode=R_EcuM_CurrentMode.currentMode.RUN
    timing event EV_StopStrtEng_020_TEV: mode-dependency=dependent-on-mode=R_UCE_stWkuMainRelSt.RCD_stWkuMainRelSt.Invalid, start-on-event=RE_StopStrtEng_020_TEV, period=0.01
    timing event EV_StopStrtEng_010_TEV: mode-dependency=dependent-on-mode=R_UCE_stWkuMainRelSt.RCD_stWkuMainRelSt.Invalid, start-on-event=RE_StopStrtEng_010_TEV, period=0.01
    mode switch event EV_StopStrtEng_013_MSE: start-on-event=RE_StopStrtEng_013_MSE, activation=ENTRY, mode=R_EcuM_CurrentMode.currentMode.RUN
    timing event EV_StopStrtEng_024_TEV: mode-dependency=dependent-on-mode=[R_UCE_stWkuMainRelSt.RCD_stWkuMainRelSt.PreMainWakeUp, R_UCE_stWkuMainRelSt.RCD_stWkuMainRelSt.PostMainWakeUp, R_UCE_stWkuMainRelSt.RCD_stWkuMainRelSt.Invalid], start-on-event=RE_StopStrtEng_024_TEV, period=0.01
    mode switch event EV_StopStrtEng_009_MSE: start-on-event=RE_StopStrtEng_009_MSE, activation=ENTRY, mode=R_EcuM_CurrentMode.currentMode.RUN
    mode switch event EV_StopStrtEng_015_MSE: start-on-event=RE_StopStrtEng_015_MSE, activation=ENTRY, mode=R_EcuM_CurrentMode.currentMode.RUN
    mode switch event EV_StopStrtEng_007_MSE: start-on-event=RE_StopStrtEng_007_MSE, activation=ENTRY, mode=R_EcuM_CurrentMode.currentMode.RUN
    timing event EV_StopStrtEng_014_TEV: mode-dependency=dependent-on-mode=R_UCE_stWkuMainRelSt.RCD_stWkuMainRelSt.Invalid, start-on-event=RE_StopStrtEng_014_TEV, period=0.01
    14 x inter runnable variable, all with sw-calibration-access=READ-WRITE, communication-approach=EXPLICIT:
      StaCtl_bEngStrtAuth: type=DT_StaCtl_bEngStrtAuth, init-value=StaCtl_bEngStrtAuth_Cst
      CoSTT_bEngStopReq: type=DT_CoSTT_bEngStopReq, init-value=CoSTT_bEngStopReq_Cst
      StopStrtEng_bVSSNwAcvAuth: type=DT_StopStrtEng_bVSSNwAcvAuth, init-value=StopStrtEng_bVSSNwAcvAuth_Cst
      CoStrt_bStrtReq: type=DT_CoStrt_bStrtReq, init-value=CoStrt_bStrtReq_Cst
      StaCtl_bEngPrepEngAuth: type=DT_StaCtl_bEngPrepEngAuth, init-value=StaCtl_bEngPrepEngAuth_Cst
      CoPTSt_bEngStrtGlblReq: type=DT_CoPTSt_bEngStrtGlblReq, init-value=CoPTSt_bEngStrtGlblReq_Cst
      CoPTSt_bEngStopReq: type=DT_CoPTSt_bEngStopReq, init-value=CoPTSt_bEngStopReq_Cst
      StaCtl_bPrepStrtAuth: type=DT_StaCtl_bPrepStrtAuth, init-value=StaCtl_bPrepStrtAuth_Cst
      StaCtl_bEngRunPrepReq: type=DT_StaCtl_bEngRunPrepReq, init-value=StaCtl_bEngRunPrepReq_Cst
      CoSTT_bEngRStrtReq: type=DT_CoSTT_bEngRStrtReq, init-value=CoSTT_bEngRStrtReq_Cst
      CoSTT_bEngCutOffReq: type=DT_CoSTT_bEngCutOffReq, init-value=CoSTT_bEngCutOffReq_Cst
      CoPTSt_bEngStrtReqVld: type=DT_CoPTSt_bEngStrtReqVld, init-value=CoPTSt_bEngStrtReqVld_Cst
      StaCtl_bEngPrepAcv: type=DT_StaCtl_bEngPrepAcv, init-value=StaCtl_bEngPrepAcv_Cst
      StaCtl_bPTProt: type=DT_StaCtl_bPTProt, init-value=StaCtl_bPTProt_Cst
    22 x runnable:
      RE_StopStrtEng_004_TEV
        10 x data receive point:
          dr_Ext_bInhStrtAMT: data-element=R_Ext_bInhStrtAMT.Ext_bInhStrtAMT
          dr_Ext_bDrvTraAMT: data-element=R_Ext_bDrvTraAMT.Ext_bDrvTraAMT
          dr_Ext_nEng: data-element=R_Ext_nEng.Ext_nEng
          dr_Ext_bDgoSenPN: data-element=R_Ext_bDgoSenPN.Ext_bDgoSenPN
          dr_Ext_rCluPHiFreq: data-element=R_Ext_rCluPHiFreq.Ext_rCluPHiFreq
          dr_ECU_bWkuMain: data-element=R_ECU_bWkuMain.ECU_bWkuMain
          dr_Ext_bATParkNeut: data-element=R_Ext_bATParkNeut.Ext_bATParkNeut
          dr_Ext_stGBxCf: data-element=R_Ext_stGBxCf.Ext_stGBxCf
          dr_Ext_stStrtCf: data-element=R_Ext_stStrtCf.Ext_stStrtCf
          dr_Ext_bCluPedPrss: data-element=R_Ext_bCluPedPrss.Ext_bCluPedPrss
        5 x data send point:
          dsp_CoPTSt_bMonRunSftyORngAMT: data-element=P_CoPTSt_bMonRunSftyORngAMT.CoPTSt_bMonRunSftyORngAMT
          dsp_CoPTSt_bDgoSftyORngAT: data-element=P_CoPTSt_bDgoSftyORngAT.CoPTSt_bDgoSftyORngAT
          ds_CoPTSt_stDrvTra: data-element=P_CoPTSt_stDrvTra.CoPTSt_stDrvTra
          dsp_CoPTSt_bDgoSftyORngAMT: data-element=P_CoPTSt_bDgoSftyORngAMT.CoPTSt_bDgoSftyORngAMT
          dsp_CoPTSt_bMonRunSftyORngAT: data-element=P_CoPTSt_bMonRunSftyORngAT.CoPTSt_bMonRunSftyORngAT
        sync call ssp_CoPTSt_SftyORngAMT: operation=R_CoPTSt_SftyORngAMT.SetEventStatus
        sync call ssp_FRM_bAcvDrvTraInvld: operation=R_FRM_bAcvDrvTraInvld.GetFunctionPermission
        sync call ssp_CoPTSt_SftyORngAT: operation=R_CoPTSt_SftyORngAT.SetEventStatus
      RE_StopStrtEng_006_TEV: read-variable=[StaCtl_bPrepStrtAuth, StaCtl_bEngStrtAuth]
        10 x data receive point:
          dr_Ext_nEng: data-element=R_Ext_nEng.Ext_nEng
          dr_Ext_posnGBxLev: data-element=R_Ext_posnGBxLev.Ext_posnGBxLev
          dr_ECU_bWkuMain: data-element=R_ECU_bWkuMain.ECU_bWkuMain
          dr_CoPTSt_stDrvTra: data-element=R_CoPTSt_stDrvTra.CoPTSt_stDrvTra
          dr_Ext_stStrtCf: data-element=R_Ext_stStrtCf.Ext_stStrtCf
          dr_Ext_bBrkPedPrss: data-element=R_Ext_bBrkPedPrss.Ext_bBrkPedPrss
          dr_Ext_bTypStrt: data-element=R_Ext_bTypStrt.Ext_bTypStrt
          dr_Ext_tCoMes: data-element=R_Ext_tCoMes.Ext_tCoMes
          dr_Ext_stGBxCf: data-element=R_Ext_stGBxCf.Ext_stGBxCf
          dr_Ext_pAirExtMes: data-element=R_Ext_pAirExtMes.Ext_pAirExtMes
        4 x data send point:
          ds_StaCtl_bStaRawAuth: data-element=P_StaCtl_bStaRawAuth.StaCtl_bStaRawAuth
          ds_StaCtl_bStaAuth: data-element=P_StaCtl_bStaAuth.StaCtl_bStaAuth
          ds_StaCtl_bStaStopReq: data-element=P_StaCtl_bStaStopReq.StaCtl_bStaStopReq
          ds_StaCtl_stStaAuth: data-element=P_StaCtl_stStaAuth.StaCtl_stStaAuth
      RE_StopStrtEng_005_MSE
        4 x data send point:
          ds_StaCtl_bStaAuth: data-element=P_StaCtl_bStaAuth.StaCtl_bStaAuth
          ds_StaCtl_bStaStopReq: data-element=P_StaCtl_bStaStopReq.StaCtl_bStaStopReq
          ds_StaCtl_stStaAuth: data-element=P_StaCtl_stStaAuth.StaCtl_stStaAuth
          ds_StaCtl_bStaRawAuth: data-element=P_StaCtl_bStaRawAuth.StaCtl_bStaRawAuth
      RE_StopStrtEng_009_MSE
        5 x data send point:
          ds_CoStrtRStrt_bVSSNwAcvAuth: data-element=P_CoStrtRStrt_bVSSNwAcvAuth.CoStrtRStrt_bVSSNwAcvAuth
          ds_CoStrtRStrt_stStopCutReq: data-element=P_CoStrtRStrt_stStopCutReq.CoStrtRStrt_stStopCutReq
          ds_CoStrtRStrt_bInh: data-element=P_CoStrtRStrt_bInh.CoStrtRStrt_bInh
          ds_CoStrtRStrt_stAcvReq: data-element=P_CoStrtRStrt_stAcvReq.CoStrtRStrt_stAcvReq
          ds_CoStrtRStrt_stEngStrtReq: data-element=P_CoStrtRStrt_stEngStrtReq.CoStrtRStrt_stEngStrtReq
      RE_StopStrtEng_011_MSE: written-variable=[StaCtl_bPrepStrtAuth, StaCtl_bEngStrtAuth, StaCtl_bEngRunPrepReq, StaCtl_bEngPrepEngAuth, StaCtl_bEngPrepAcv]
      RE_StopStrtEng_023_MSE
        5 x data send point:
          ds_CoTqRStrt_bChaTqAvl: data-element=P_CoTqRStrt_bChaTqAvl.CoTqRStrt_bChaTqAvl
          ds_CoTqRStrt_bTraTqAuthRaw: data-element=P_CoTqRStrt_bTraTqAuthRaw.CoTqRStrt_bTraTqAuthRaw
          ds_CoTqRStrt_bTraCoplAuth: data-element=P_CoTqRStrt_bTraCoplAuth.CoTqRStrt_bTraCoplAuth
          ds_CoTqRStrt_bChaTqCrt: data-element=P_CoTqRStrt_bChaTqCrt.CoTqRStrt_bChaTqCrt
          ds_CoTqRStrt_bEngStrtSuc: data-element=P_CoTqRStrt_bEngStrtSuc.CoTqRStrt_bEngStrtSuc
      RE_StopStrtEng_017_MSE: written-variable=CoStrt_bStrtReq
        data send point ds_CoStrt_bStrtAuth: data-element=P_CoStrt_bStrtAuth.CoStrt_bStrtAuth
      RE_StopStrtEng_007_MSE: written-variable=StaCtl_bPTProt
        data send point ds_StaCtl_bStaProt: data-element=P_StaCtl_bStaProt.StaCtl_bStaProt
      RE_StopStrtEng_014_TEV: read-variable=[CoSTT_bEngCutOffReq, CoPTSt_bEngStrtGlblReq, StaCtl_bEngRunPrepReq, CoSTT_bEngRStrtReq, StaCtl_bEngPrepAcv, CoPTSt_bEngStopReq, StaCtl_bEngPrepEngAuth, CoSTT_bEngStopReq]
        19 x data receive point:
          dr_TqSys_bTqSysAcv: data-element=R_TqSys_bTqSysAcv.TqSys_bTqSysAcv
          dr_PARM_bEngRstrtAutnAvl: data-element=R_PARM_bEngRstrtAutnAvl.PARM_bEngRstrtAutnAvl
          dr_CoTqRStrt_bTraTqAuthRaw: data-element=R_CoTqRStrt_bTraTqAuthRaw.CoTqRStrt_bTraTqAuthRaw
          dr_CoPtASE_bEngStrtTypASEReq: data-element=R_CoPtASE_bEngStrtTypASEReq.CoPtASE_bEngStrtTypASEReq
          dr_Ext_tCoMes: data-element=R_Ext_tCoMes.Ext_tCoMes
          dr_EngReqH_bEngRStrtAutnAvl: data-element=R_EngReqH_bEngRStrtAutnAvl.EngReqH_bEngRStrtAutnAvl
          dr_CoPtASE_bEngCutOffReq: data-element=R_CoPtASE_bEngCutOffReq.CoPtASE_bEngCutOffReq
          dr_Ext_bAcvInjCutOff: data-element=R_Ext_bAcvInjCutOff.Ext_bAcvInjCutOff
          dr_ECU_bWkuMain: data-element=R_ECU_bWkuMain.ECU_bWkuMain
          dr_CoTqRStrt_bEngStrtSuc: data-element=R_CoTqRStrt_bEngStrtSuc.CoTqRStrt_bEngStrtSuc
          dr_CoPtASE_bEngRStrtTypASEReq: data-element=R_CoPtASE_bEngRStrtTypASEReq.CoPtASE_bEngRStrtTypASEReq
          dr_InjCtl_mfFuReq: data-element=R_InjCtl_mfFuReq.InjCtl_mfFuReq
          dr_CoEs_bAcvInjCutOffSTTEs: data-element=R_CoEs_bAcvInjCutOffSTTEs.CoEs_bAcvInjCutOffSTTEs
          dr_IgSys_bAcvStructAdv: data-element=R_IgSys_bAcvStructAdv.IgSys_bAcvStructAdv
          dr_Ext_nEng: data-element=R_Ext_nEng.Ext_nEng
          dr_CoPtUH_bEngStallReq: data-element=R_CoPtUH_bEngStallReq.CoPtUH_bEngStallReq
          dr_CoSync_bDetNNull: data-element=R_CoSync_bDetNNull.CoSync_bDetNNull
          dr_IgSys_bAcvStructAir: data-element=R_IgSys_bAcvStructAir.IgSys_bAcvStructAir
          dr_CoOptmEl_stElEProv: data-element=R_CoOptmEl_stElEProv.CoOptmEl_stElEProv
        6 x data send point:
          ds_CoPTSt_stEng: data-element=P_CoPTSt_stEng.CoPTSt_stEng
          ds_CoPTSt_bEngRunSTT: data-element=P_CoPTSt_bEngRunSTT.CoPTSt_bEngRunSTT
          ds_CoPTStNew_stEngPrec: data-element=P_CoPTStNew_stEngPrec.CoPTStNew_stEngPrec
          ds_CoPTSt_bEngStop: data-element=P_CoPTSt_bEngStop.CoPTSt_bEngStop
          ds_CoPTStNew_stEng: data-element=P_CoPTStNew_stEng.CoPTStNew_stEng
          ds_CoPTSt_bEngRun: data-element=P_CoPTSt_bEngRun.CoPTSt_bEngRun
      RE_StopStrtEng_022_TEV
        5 x data receive point:
          dr_CoPtUH_stPwt: data-element=R_CoPtUH_stPwt.CoPtUH_stPwt
          dr_CoOptmEl_stElEProv: data-element=R_CoOptmEl_stElEProv.CoOptmEl_stElEProv
          dr_CoPtUH_bEngStopReq: data-element=R_CoPtUH_bEngStopReq.CoPtUH_bEngStopReq
          dr_CoPtASE_stPwt: data-element=R_CoPtASE_stPwt.CoPtASE_stPwt
          dr_CoPTStNew_stEng: data-element=R_CoPTStNew_stEng.CoPTStNew_stEng
        data send point ds_CoPtSynt_bStopIp: data-element=P_CoPtSynt_bStopIp.CoPtSynt_bStopIp
        data send point ds_CoPtSynt_stPwt: data-element=P_CoPtSynt_stPwt.CoPtSynt_stPwt
      RE_StopStrtEng_020_TEV: read-variable=CoStrt_bStrtReq, written-variable=StopStrtEng_bVSSNwAcvAuth
        4 x data receive point:
          dr_EngReqH_bDetPresAirUnfav: data-element=R_EngReqH_bDetPresAirUnfav.EngReqH_bDetPresAirUnfav
          dr_CoEmCkg_stStrtRstrtFbCmd: data-element=R_CoEmCkg_stStrtRstrtFbCmd.CoEmCkg_stStrtRstrtFbCmd
          dr_TqAdp_stCdnNxtCkg: data-element=R_TqAdp_stCdnNxtCkg.TqAdp_stCdnNxtCkg
          dr_CoEmSTT_tiVSSTmrStrtAuth: data-element=R_CoEmSTT_tiVSSTmrStrtAuth.CoEmSTT_tiVSSTmrStrtAuth
        data send point ds_StopStrtEng_stCdnNxtCkg: data-element=P_StopStrtEng_stCdnNxtCkg.StopStrtEng_stCdnNxtCkg
        sync call ssp_FRM_bStrtPrf: operation=R_FRM_bStrtPrf.GetFunctionPermission
      RE_StopStrtEng_021_MSE
        data send point ds_CoPtSynt_bStopIp: data-element=P_CoPtSynt_bStopIp.CoPtSynt_bStopIp
        data send point ds_CoPtSynt_stPwt: data-element=P_CoPtSynt_stPwt.CoPtSynt_stPwt
      RE_StopStrtEng_010_TEV: read-variable=[CoSTT_bEngStopReq, CoStrt_bStrtReq, CoSTT_bEngRStrtReq, CoPTSt_bEngStopReq, CoPTSt_bEngStrtGlblReq, CoSTT_bEngCutOffReq, StopStrtEng_bVSSNwAcvAuth]
        17 x data receive point:
          dr_Afts_bSpcFactOnDeacInh: data-element=R_Afts_bSpcFactOnDeacInh.Afts_bSpcFactOnDeacInh
          dr_CoPtASE_bAltStrtTypASEReq: data-element=R_CoPtASE_bAltStrtTypASEReq.CoPtASE_bAltStrtTypASEReq
          dr_CoEmSTT_tiVSSTmrStrtAuth: data-element=R_CoEmSTT_tiVSSTmrStrtAuth.CoEmSTT_tiVSSTmrStrtAuth
          dr_ECU_bWkuMain: data-element=R_ECU_bWkuMain.ECU_bWkuMain
          dr_CoPtASE_bEngCutOffReq: data-element=R_CoPtASE_bEngCutOffReq.CoPtASE_bEngCutOffReq
          dr_CoPTStNew_stEng: data-element=R_CoPTStNew_stEng.CoPTStNew_stEng
          dr_CoPtASE_bEngStrtTypASEReq: data-element=R_CoPtASE_bEngStrtTypASEReq.CoPtASE_bEngStrtTypASEReq
          dr_CoPtASE_bEngRStrtTypASEReq: data-element=R_CoPtASE_bEngRStrtTypASEReq.CoPtASE_bEngRStrtTypASEReq
          dr_CoPtASE_bAltRStrtTypASEReq: data-element=R_CoPtASE_bAltRStrtTypASEReq.CoPtASE_bAltRStrtTypASEReq
          dr_CoPtASE_bCdnInhRStrt: data-element=R_CoPtASE_bCdnInhRStrt.CoPtASE_bCdnInhRStrt
          dr_CoStrt_bStrtAuth: data-element=R_CoStrt_bStrtAuth.CoStrt_bStrtAuth
          dr_CoPtASE_bEngStallReq: data-element=R_CoPtASE_bEngStallReq.CoPtASE_bEngStallReq
          dr_Afts_bSpcFactOffDeacInh: data-element=R_Afts_bSpcFactOffDeacInh.Afts_bSpcFactOffDeacInh
          dr_CoPtASE_bVSSNwAcvAuth: data-element=R_CoPtASE_bVSSNwAcvAuth.CoPtASE_bVSSNwAcvAuth
          dr_CoPtUH_bVSSNwAcvAuth: data-element=R_CoPtUH_bVSSNwAcvAuth.CoPtUH_bVSSNwAcvAuth
          dr_CoPtUH_bAltRStrtReq: data-element=R_CoPtUH_bAltRStrtReq.CoPtUH_bAltRStrtReq
          dr_CoPtUH_bCdnInhRStrt: data-element=R_CoPtUH_bCdnInhRStrt.CoPtUH_bCdnInhRStrt
        5 x data send point:
          ds_CoStrtRStrt_stAcvReq: data-element=P_CoStrtRStrt_stAcvReq.CoStrtRStrt_stAcvReq
          ds_CoStrtRStrt_bInh: data-element=P_CoStrtRStrt_bInh.CoStrtRStrt_bInh
          ds_CoStrtRStrt_stStopCutReq: data-element=P_CoStrtRStrt_stStopCutReq.CoStrtRStrt_stStopCutReq
          ds_CoStrtRStrt_stEngStrtReq: data-element=P_CoStrtRStrt_stEngStrtReq.CoStrtRStrt_stEngStrtReq
          ds_CoStrtRStrt_bVSSNwAcvAuth: data-element=P_CoStrtRStrt_bVSSNwAcvAuth.CoStrtRStrt_bVSSNwAcvAuth
      RE_StopStrtEng_018_TEV: read-variable=CoPTSt_bEngStrtReqVld, written-variable=CoStrt_bStrtReq
        data receive point dr_Ext_bDrvStrtReq: data-element=R_Ext_bDrvStrtReq.Ext_bDrvStrtReq
        data receive point dr_StaCtl_bStaAuth: data-element=R_StaCtl_bStaAuth.StaCtl_bStaAuth
        data send point ds_CoStrt_bStrtAuth: data-element=P_CoStrt_bStrtAuth.CoStrt_bStrtAuth
      RE_StopStrtEng_016_TEV: written-variable=[CoPTSt_bEngStopReq, CoSTT_bEngCutOffReq, CoPTSt_bEngStrtGlblReq, CoSTT_bEngRStrtReq, CoPTSt_bEngStrtReqVld, CoSTT_bEngStopReq]
        25 x data receive point:
          dr_CoPtFH_bEngCutOffReq: data-element=R_CoPtFH_bEngCutOffReq.CoPtFH_bEngCutOffReq
          dr_ECU_bWkuMain: data-element=R_ECU_bWkuMain.ECU_bWkuMain
          dr_CoPTStNew_stEng: data-element=R_CoPTStNew_stEng.CoPTStNew_stEng
          dr_CoPtASE_bEngStallReq: data-element=R_CoPtASE_bEngStallReq.CoPtASE_bEngStallReq
          dr_Ext_bRCDLine: data-element=R_Ext_bRCDLine.Ext_bRCDLine
          dr_CoPtUH_bEngStallReq: data-element=R_CoPtUH_bEngStallReq.CoPtUH_bEngStallReq
          dr_Veh_spdVeh: data-element=R_Veh_spdVeh.Veh_spdVeh
          dr_Ext_bCoReqVehCf_bEngStrtReq: data-element=R_Ext_bCoReqVehCf_bEngStrtReq.Ext_bCoReqVehCf_bEngStrtReq
          dr_CoPtUH_bEngStopReq: data-element=R_CoPtUH_bEngStopReq.CoPtUH_bEngStopReq
          dr_Ext_bSTTCf: data-element=R_Ext_bSTTCf.Ext_bSTTCf
          dr_CoPtASE_bEngCutOffReq: data-element=R_CoPtASE_bEngCutOffReq.CoPtASE_bEngCutOffReq
          dr_CoPtFH_bEngRunReq: data-element=R_CoPtFH_bEngRunReq.CoPtFH_bEngRunReq
          dr_CoPtFH_bEngStopReq: data-element=R_CoPtFH_bEngStopReq.CoPtFH_bEngStopReq
          dr_Ext_stFuTypCf: data-element=R_Ext_stFuTypCf.Ext_stFuTypCf
          dr_Ext_bEngStopReq: data-element=R_Ext_bEngStopReq.Ext_bEngStopReq
          dr_StaCtl_bStaProt: data-element=R_StaCtl_bStaProt.StaCtl_bStaProt
          dr_CoReqVeh_bEngStrtReq: data-element=R_CoReqVeh_bEngStrtReq.CoReqVeh_bEngStrtReq
          dr_Ext_bEngStrtReq: data-element=R_Ext_bEngStrtReq.Ext_bEngStrtReq
          dr_CoPtUH_bEngRStrtReq: data-element=R_CoPtUH_bEngRStrtReq.CoPtUH_bEngRStrtReq
          dr_CoOptmEl_stElEProv: data-element=R_CoOptmEl_stElEProv.CoOptmEl_stElEProv
          dr_Ext_bASECf: data-element=R_Ext_bASECf.Ext_bASECf
          dr_CoPtUH_bEngCutOffReq: data-element=R_CoPtUH_bEngCutOffReq.CoPtUH_bEngCutOffReq
          dr_AccP_rAccP: data-element=R_AccP_rAccP.AccP_rAccP
          dr_Ext_nEng: data-element=R_Ext_nEng.Ext_nEng
          dr_Ext_stStrtCf: data-element=R_Ext_stStrtCf.Ext_stStrtCf
        data send point ds_CoPTSt_bMainEngStopReq: data-element=P_CoPTSt_bMainEngStopReq.CoPTSt_bMainEngStopReq
        10 x sync call:
          ssp_FRM_bAcvCoPTStEngStop: operation=R_FRM_bAcvCoPTStEngStop.GetFunctionPermission
          ssp_FRM_bAcvEngCutOffRCDLo: operation=R_FRM_bAcvEngCutOffRCDLo.GetFunctionPermission
          ssp_FRM_bAcvCoPTStByp_nEng: operation=R_FRM_bAcvCoPTStByp_nEng.GetFunctionPermission
          ssp_FRM_bAcvCoPTStByp_spdVeh: operation=R_FRM_bAcvCoPTStByp_spdVeh.GetFunctionPermission
          ssp_CoSTT_ORngCutOffReq: operation=R_CoSTT_ORngCutOffReq.SetEventStatus
          ssp_FRM_bInhEngCutOff: operation=R_FRM_bInhEngCutOff.GetFunctionPermission
          ssp_FRM_bAcvEngCutOff: operation=R_FRM_bAcvEngCutOff.GetFunctionPermission
          ssp_FRM_bInhSTT: operation=R_FRM_bInhSTT.GetFunctionPermission
          ssp_CoSTT_ORngStopReq: operation=R_CoSTT_ORngStopReq.SetEventStatus
          ssp_CoPTSt_ORngMplReq: operation=R_CoPTSt_ORngMplReq.SetEventStatus
      RE_StopStrtEng_008_TEV: written-variable=StaCtl_bPTProt
        data receive point dr_CoEmCkg_stStrtRstrtFbCmd: data-element=R_CoEmCkg_stStrtRstrtFbCmd.CoEmCkg_stStrtRstrtFbCmd
        data receive point dr_CoPTSt_bEngRunSTT: data-element=R_CoPTSt_bEngRunSTT.CoPTSt_bEngRunSTT
        data send point ds_StaCtl_bStaProt: data-element=P_StaCtl_bStaProt.StaCtl_bStaProt
      RE_StopStrtEng_013_MSE
        6 x data send point:
          ds_CoPTSt_bEngRunSTT: data-element=P_CoPTSt_bEngRunSTT.CoPTSt_bEngRunSTT
          ds_CoPTSt_bEngRun: data-element=P_CoPTSt_bEngRun.CoPTSt_bEngRun
          ds_CoPTSt_bEngStop: data-element=P_CoPTSt_bEngStop.CoPTSt_bEngStop
          ds_CoPTStNew_stEngPrec: data-element=P_CoPTStNew_stEngPrec.CoPTStNew_stEngPrec
          ds_CoPTStNew_stEng: data-element=P_CoPTStNew_stEng.CoPTStNew_stEng
          ds_CoPTSt_stEng: data-element=P_CoPTSt_stEng.CoPTSt_stEng
      RE_StopStrtEng_003_MSE
        5 x data send point:
          ds_CoPTSt_stDrvTra: data-element=P_CoPTSt_stDrvTra.CoPTSt_stDrvTra
          dsp_CoPTSt_bMonRunSftyORngAT: data-element=P_CoPTSt_bMonRunSftyORngAT.CoPTSt_bMonRunSftyORngAT
          dsp_CoPTSt_bDgoSftyORngAMT: data-element=P_CoPTSt_bDgoSftyORngAMT.CoPTSt_bDgoSftyORngAMT
          dsp_CoPTSt_bMonRunSftyORngAMT: data-element=P_CoPTSt_bMonRunSftyORngAMT.CoPTSt_bMonRunSftyORngAMT
          dsp_CoPTSt_bDgoSftyORngAT: data-element=P_CoPTSt_bDgoSftyORngAT.CoPTSt_bDgoSftyORngAT
      RE_StopStrtEng_015_MSE: written-variable=[CoPTSt_bEngStrtGlblReq, CoPTSt_bEngStopReq, CoSTT_bEngStopReq, CoSTT_bEngRStrtReq, CoSTT_bEngCutOffReq, CoPTSt_bEngStrtReqVld]
        data send point ds_CoPTSt_bMainEngStopReq: data-element=P_CoPTSt_bMainEngStopReq.CoPTSt_bMainEngStopReq
      RE_StopStrtEng_012_TEV: read-variable=StaCtl_bPTProt, written-variable=[StaCtl_bEngPrepEngAuth, StaCtl_bEngStrtAuth, StaCtl_bEngPrepAcv, StaCtl_bPrepStrtAuth, StaCtl_bEngRunPrepReq]
        7 x data receive point:
          dr_GlwCtl_bEngRunReq: data-element=R_GlwCtl_bEngRunReq.GlwCtl_bEngRunReq
          dr_CoPTSt_bMainEngStopReq: data-element=R_CoPTSt_bMainEngStopReq.CoPTSt_bMainEngStopReq
          dr_Ext_bGslEngPrepReq: data-element=R_Ext_bGslEngPrepReq.Ext_bGslEngPrepReq
          dr_Ext_stFuTypCf: data-element=R_Ext_stFuTypCf.Ext_stFuTypCf
          dr_Sfty_bInhDrvTraSfty: data-element=R_Sfty_bInhDrvTraSfty.Sfty_bInhDrvTraSfty
          dr_CoEmCkg_bWaitStrtReq: data-element=R_CoEmCkg_bWaitStrtReq.CoEmCkg_bWaitStrtReq
          dr_GlwCtl_bEngRunAuth: data-element=R_GlwCtl_bEngRunAuth.GlwCtl_bEngRunAuth
        sync call ssp_FRM_bInhSta: operation=R_FRM_bInhSta.GetFunctionPermission
      RE_StopStrtEng_019_MSE: written-variable=StopStrtEng_bVSSNwAcvAuth
        data send point ds_StopStrtEng_stCdnNxtCkg: data-element=P_StopStrtEng_stCdnNxtCkg.StopStrtEng_stCdnNxtCkg
      RE_StopStrtEng_024_TEV
        9 x data receive point:
          dr_CoEmCkg_stStrtRstrtFbCmd: data-element=R_CoEmCkg_stStrtRstrtFbCmd.CoEmCkg_stStrtRstrtFbCmd
          dr_Ext_tOilMes: data-element=R_Ext_tOilMes.Ext_tOilMes
          dr_InjCtl_mfFuReq: data-element=R_InjCtl_mfFuReq.InjCtl_mfFuReq
          dr_Ext_tCoMes: data-element=R_Ext_tCoMes.Ext_tCoMes
          dr_CoPt_bSIP: data-element=R_CoPt_bSIP.CoPt_bSIP
          dr_PredEs_nFast: data-element=R_PredEs_nFast.PredEs_nFast
          dr_TqSys_nTarIdl: data-element=R_TqSys_nTarIdl.TqSys_nTarIdl
          dr_Ext_nEng: data-element=R_Ext_nEng.Ext_nEng
          dr_Ext_pAirExtMes: data-element=R_Ext_pAirExtMes.Ext_pAirExtMes
        5 x data send point:
          ds_CoTqRStrt_bTraTqAuthRaw: data-element=P_CoTqRStrt_bTraTqAuthRaw.CoTqRStrt_bTraTqAuthRaw
          ds_CoTqRStrt_bEngStrtSuc: data-element=P_CoTqRStrt_bEngStrtSuc.CoTqRStrt_bEngStrtSuc
          ds_CoTqRStrt_bChaTqCrt: data-element=P_CoTqRStrt_bChaTqCrt.CoTqRStrt_bChaTqCrt
          ds_CoTqRStrt_bChaTqAvl: data-element=P_CoTqRStrt_bChaTqAvl.CoTqRStrt_bChaTqAvl
          ds_CoTqRStrt_bTraCoplAuth: data-element=P_CoTqRStrt_bTraCoplAuth.CoTqRStrt_bTraCoplAuth
        sync call ssp_FRM_bAcvPrmCoTqRStrt: operation=R_FRM_bAcvPrmCoTqRStrt.GetFunctionPermission
  swc implementation Imp_StopStrtEng: programming-language=C, behavior=IB_StopStrtEng
    code-descriptors:
      code CodeDescriptor: type=SRC
        47 x xfile:
          StopStrtEng_016_calibrations_h: url=StopStrtEng_016_calibrations.h
          StopStrtEng_008_calibrations_h: url=StopStrtEng_008_calibrations.h
          StopStrtEng_020_TEV_fct_c: url=StopStrtEng_020_TEV_fct.c
          StopStrtEng_018_calibrations_h: url=StopStrtEng_018_calibrations.h
          StopStrtEng_024_TEV_fct_h: url=StopStrtEng_024_TEV_fct.h
          StopStrtEng_014_calibrations_c: url=StopStrtEng_014_calibrations.c
          StopStrtEng_010_TEV_fct_h: url=StopStrtEng_010_TEV_fct.h
          StopStrtEng_010_TEV_fct_c: url=StopStrtEng_010_TEV_fct.c
          StopStrtEng_014_TEV_fct_h: url=StopStrtEng_014_TEV_fct.h
          StopStrtEng_018_TEV_fct_h: url=StopStrtEng_018_TEV_fct.h
          StopStrtEng_016_TEV_fct_h: url=StopStrtEng_016_TEV_fct.h
          StopStrtEng_024_TEV_fct_c: url=StopStrtEng_024_TEV_fct.c
          StopStrtEng_014_calibrations_h: url=StopStrtEng_014_calibrations.h
          StopStrtEng_020_calibrations_h: url=StopStrtEng_020_calibrations.h
          StopStrtEng_024_calibrations_h: url=StopStrtEng_024_calibrations.h
          StopStrtEng_MemMap_h: url=StopStrtEng_MemMap.h
          StopStrtEng_008_calibrations_c: url=StopStrtEng_008_calibrations.c
          StopStrtEng_024_calibrations_c: url=StopStrtEng_024_calibrations.c
          StopStrtEng_020_TEV_fct_h: url=StopStrtEng_020_TEV_fct.h
          StopStrtEng_004_TEV_fct_c: url=StopStrtEng_004_TEV_fct.c
          StopStrtEng_006_TEV_fct_c: url=StopStrtEng_006_TEV_fct.c
          StopStrtEng_020_calibrations_c: url=StopStrtEng_020_calibrations.c
          StopStrtEng_006_calibrations_h: url=StopStrtEng_006_calibrations.h
          StopStrtEng_006_TEV_fct_h: url=StopStrtEng_006_TEV_fct.h
          StopStrtEng_012_TEV_fct_c: url=StopStrtEng_012_TEV_fct.c
          StopStrtEng_h: url=StopStrtEng.h
          StopStrtEng_018_TEV_fct_c: url=StopStrtEng_018_TEV_fct.c
          StopStrtEng_022_calibrations_h: url=StopStrtEng_022_calibrations.h
          StopStrtEng_012_TEV_fct_h: url=StopStrtEng_012_TEV_fct.h
          StopStrtEng_004_calibrations_c: url=StopStrtEng_004_calibrations.c
          StopStrtEng_022_TEV_fct_c: url=StopStrtEng_022_TEV_fct.c
          StopStrtEng_c: url=StopStrtEng.c
          StopStrtEng_016_TEV_fct_c: url=StopStrtEng_016_TEV_fct.c
          StopStrtEng_012_calibrations_h: url=StopStrtEng_012_calibrations.h
          StopStrtEng_004_calibrations_h: url=StopStrtEng_004_calibrations.h
          StopStrtEng_016_calibrations_c: url=StopStrtEng_016_calibrations.c
          StopStrtEng_010_calibrations_c: url=StopStrtEng_010_calibrations.c
          StopStrtEng_006_calibrations_c: url=StopStrtEng_006_calibrations.c
          StopStrtEng_010_calibrations_h: url=StopStrtEng_010_calibrations.h
          StopStrtEng_004_TEV_fct_h: url=StopStrtEng_004_TEV_fct.h
          StopStrtEng_022_calibrations_c: url=StopStrtEng_022_calibrations.c
          StopStrtEng_014_TEV_fct_c: url=StopStrtEng_014_TEV_fct.c
          StopStrtEng_022_TEV_fct_h: url=StopStrtEng_022_TEV_fct.h
          StopStrtEng_008_TEV_fct_h: url=StopStrtEng_008_TEV_fct.h
          StopStrtEng_018_calibrations_c: url=StopStrtEng_018_calibrations.c
          StopStrtEng_012_calibrations_c: url=StopStrtEng_012_calibrations.c
          StopStrtEng_008_TEV_fct_c: url=StopStrtEng_008_TEV_fct.c
package /Components/SWC_StopStrtEng/StopStrtEng_IRVDatatypes
  14 x boolean type, all with base-type=boolean:
    DT_CoPTSt_bEngStopReq
    DT_CoPTSt_bEngStrtGlblReq
    DT_CoPTSt_bEngStrtReqVld
    DT_CoStrt_bStrtReq
    DT_CoSTT_bEngCutOffReq
    DT_CoSTT_bEngRStrtReq
    DT_CoSTT_bEngStopReq
    DT_StaCtl_bEngPrepAcv
    DT_StaCtl_bEngPrepEngAuth
    DT_StaCtl_bEngRunPrepReq
    DT_StaCtl_bEngStrtAuth
    DT_StaCtl_bPrepStrtAuth
    DT_StaCtl_bPTProt
    DT_StopStrtEng_bVSSNwAcvAuth
